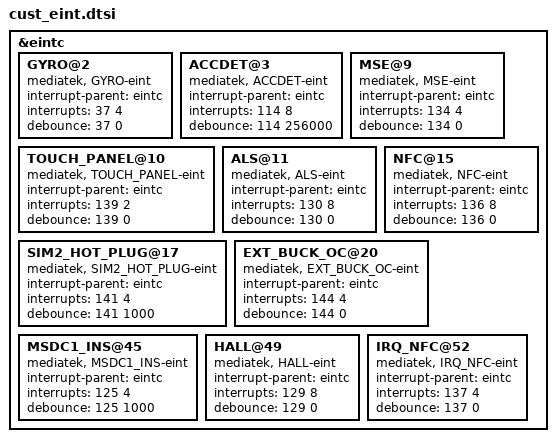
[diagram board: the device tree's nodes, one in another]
/*
 * Generated by MTK SP DrvGen Version 03.13.6 for MT6752. Copyright MediaTek Inc. (C) 2013.
 * Fri Nov 20 16:15:00 2015
 * Do Not Modify the File.
 */

/*************************
 * EINT DTSI File
*************************/

&eintc {
	GYRO@2 {
		compatible = "mediatek, GYRO-eint";
		interrupt-parent = <&eintc>;
		interrupts = <37 4>;
		debounce = <37 0>;
	};

	ACCDET@3 {
		compatible = "mediatek, ACCDET-eint";
		interrupt-parent = <&eintc>;
		interrupts = <114 8>;
		debounce = <114 256000>;
	};

	MSE@9 {
		compatible = "mediatek, MSE-eint";
		interrupt-parent = <&eintc>;
		interrupts = <134 4>;
		debounce = <134 0>;
	};

	TOUCH_PANEL@10 {
		compatible = "mediatek, TOUCH_PANEL-eint";
		interrupt-parent = <&eintc>;
		interrupts = <139 2>;
		debounce = <139 0>;
	};

	ALS@11 {
		compatible = "mediatek, ALS-eint";
		interrupt-parent = <&eintc>;
		interrupts = <130 8>;
		debounce = <130 0>;
	};

	NFC@15 {
		compatible = "mediatek, NFC-eint";
		interrupt-parent = <&eintc>;
		interrupts = <136 8>;
		debounce = <136 0>;
	};

	SIM2_HOT_PLUG@17 {
		compatible = "mediatek, SIM2_HOT_PLUG-eint";
		interrupt-parent = <&eintc>;
		interrupts = <141 4>;
		debounce = <141 1000>;
	};

	EXT_BUCK_OC@20 {
		compatible = "mediatek, EXT_BUCK_OC-eint";
		interrupt-parent = <&eintc>;
		interrupts = <144 4>;
		debounce = <144 0>;
	};

	MSDC1_INS@45 {
		compatible = "mediatek, MSDC1_INS-eint";
		interrupt-parent = <&eintc>;
		interrupts = <125 4>;
		debounce = <125 1000>;
	};

	HALL@49 {
		compatible = "mediatek, HALL-eint";
		interrupt-parent = <&eintc>;
		interrupts = <129 8>;
		debounce = <129 0>;
	};

	IRQ_NFC@52 {
		compatible = "mediatek, IRQ_NFC-eint";
		interrupt-parent = <&eintc>;
		interrupts = <137 4>;
		debounce = <137 0>;
	};

};
